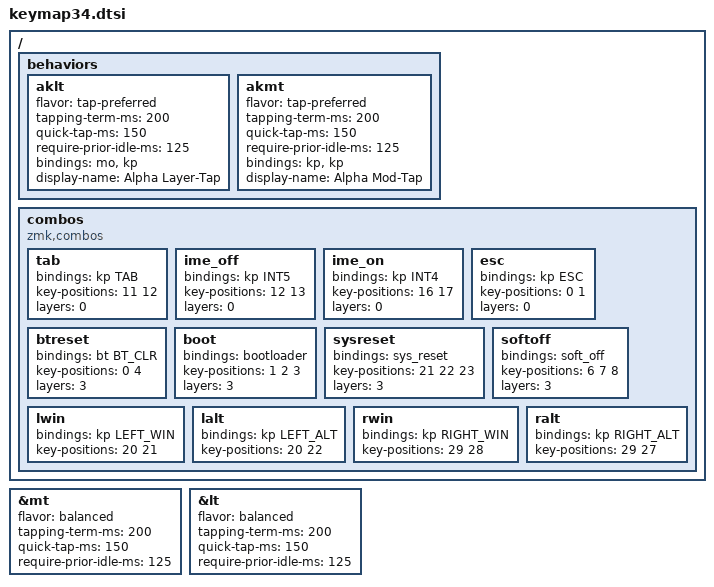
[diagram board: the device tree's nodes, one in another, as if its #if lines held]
/*
 * fue/keymap34.dtsi
 * jisaku_1(40キー) / aerogu34(34キー) 共通キーマップ定義
 *
 * ★キーマップを変えるときはこのファイルだけを編集する★
 * 変更をmainへpush後、各キーボードのリポジトリでGitHub Actionsを実行
 * (Run workflow)してビルドし直すと両機に反映される。
 *
 * 共通論理レイアウト(キー位置0〜33):
 *   0- 9: 上段10キー / 10-19: 中段10キー / 20-29: 下段10キー
 *  30-33: 親指4キー(SPACE / GRAVE / BACKSPACE / ENTER)
 * jisaku_1は最下段外側3キー×2を&noneで埋めて同一レイアウトにする。
 */

#ifndef FUE_KEYMAP34_DTSI
#define FUE_KEYMAP34_DTSI

#include <behaviors.dtsi>
#include <dt-bindings/zmk/keys.h>
#include <dt-bindings/zmk/bt.h>
#include <dt-bindings/zmk/pointing.h>

// ===== 実行時に変更できるホールドタップ(2026-11-27) =====
// zmk-feature-runtime-holdtap モジュールが west.yml にあれば、&lt / &mt と下の
// &aklt / &akmt を「zmk,behavior-runtime-hold-tap」ドライバに切り替える。
// flavor・tapping-term-ms などを DYA Studio の詳細設定(rt_holdtap)から
// ファーム書き換えなしで変更でき、下に書いた値はその既定値になる。
// モジュールが無いキーボードでは従来どおり標準ドライバのままビルドできる。
// (ホールドタップのドライバは全ホールドタップで揃える必要がある)
#if __has_include(<behaviors/runtime_hold_tap.dtsi>)
#include <behaviors/runtime_hold_tap.dtsi>
#define FUE_HOLD_TAP_COMPATIBLE ZMK_RUNTIME_HOLD_TAP_COMPATIBLE
#else
#define FUE_HOLD_TAP_COMPATIBLE "zmk,behavior-hold-tap"
#endif

// ===== JIS配列用キーコード定義(OS側が日本語配列設定の場合に正しい記号を出す) =====
#define JP_DQUOTE     AT                // "
#define JP_AMPERSAND  CARET             // &
#define JP_QUOTE      AMPERSAND         // '
#define JP_EQUAL      UNDER             // =
#define JP_CARET      EQUAL             // ^
#define JP_YEN        INT3              // ¥
#define JP_PLUS       COLON             // +
#define JP_TILDE      PLUS              // ~
#define JP_PIPE       LS(INT3)          // |
#define JP_AT         LEFT_BRACKET      // @
#define JP_COLON      SINGLE_QUOTE      // :
#define JP_ASTERISK   DOUBLE_QUOTES     // *
#define JP_BACKQUOTE  LEFT_BRACE        // `
#define JP_UNDERSCORE LS(INT1)          // _
#define JP_LBRACKET   RIGHT_BRACKET     // [
#define JP_RBRACKET   BACKSLASH         // ]
#define JP_LPAREN     ASTERISK          // (
#define JP_RPAREN     LEFT_PARENTHESIS  // )
#define JP_LBRACE     RIGHT_BRACE       // {
#define JP_RBRACE     PIPE              // }
#define JP_KANA       LANGUAGE_1        // かな
#define JP_EISU       LANGUAGE_2        // 英数
#define JP_HANZEN     GRAVE             // 半角/全角

// ===== ホールドタップ誤爆対策 =====
// balanced: 別キーが押して離されるまで完了したら長押し判定
// require-prior-idle-ms: 直前の打鍵から125ms以内は問答無用で単押し判定(ローリング誤爆根絶)
// quick-tap-ms: タップ直後150ms以内の再押下は単押し(キーリピート有効化)
&mt {
    flavor = "balanced";
    tapping-term-ms = <200>;
    quick-tap-ms = <150>;
    require-prior-idle-ms = <125>;
};

&lt {
    flavor = "balanced";
    tapping-term-ms = <200>;
    quick-tap-ms = <150>;
    require-prior-idle-ms = <125>;
};
// ↑ &mt / &lt は親指キー用(素早いレイヤー切替のため balanced のまま)。

// ===== 文字キー用ホールドタップ(2026-11-27) =====
// 文字キー(D/K/A/Z…)に balanced を使うと、「K押下→U押して離す→K離す」の
// ローリング(ローマ字の "ku" 等)が長押し判定になり、Win+Tab や BT切替が誤爆していた。
// 文字キーは tap-preferred にして「単独で tapping-term 以上押し続けた時だけ」長押しにする。
//   - 他キーを挟んでも長押しにならない → KU / DE / AT などのローリングで誤爆しない
//   - Kを押したままトラックボールを回す → 200ms後にScrollレイヤー(従来どおり)
//   - Ctrl+C 等は A を押したまま C → A を200ms以上保持すればCtrl+Cとして送出される
// DYA Studio上では「Alpha Layer-Tap」「Alpha Mod-Tap」として選択できる。
/ {
    behaviors {
        aklt: aklt {
            compatible = FUE_HOLD_TAP_COMPATIBLE;
            #binding-cells = <2>;
            flavor = "tap-preferred";
            tapping-term-ms = <200>;
            quick-tap-ms = <150>;
            require-prior-idle-ms = <125>;
            bindings = <&mo>, <&kp>;
            display-name = "Alpha Layer-Tap";
        };

        akmt: akmt {
            compatible = FUE_HOLD_TAP_COMPATIBLE;
            #binding-cells = <2>;
            flavor = "tap-preferred";
            tapping-term-ms = <200>;
            quick-tap-ms = <150>;
            require-prior-idle-ms = <125>;
            bindings = <&kp>, <&kp>;
            display-name = "Alpha Mod-Tap";
        };
    };
};

// ===== コンボ定義(両機共通: キー位置0〜29は同一) =====
/ {
    combos {
        compatible = "zmk,combos";

        tab {
            bindings = <&kp TAB>;
            key-positions = <11 12>;
            layers = <0>;
        };

        // ----- 日本語入力の切替 (2026-11-27) -----
        // D+F = IMEオフ(無変換) / J+K = IMEオン(変換)。今の状態に関係なく確実に切り替わる。
        // ※ Windows の MS-IME 設定で「無変換キー: IME-オフ」「変換キー: IME-オン」にしておくこと。
        // (旧 D+F=Shift+Tab は NumNavレイヤーの N に移動)
        ime_off {
            bindings = <&kp INT5>;
            key-positions = <12 13>;
            layers = <0>;
        };

        ime_on {
            bindings = <&kp INT4>;
            key-positions = <16 17>;
            layers = <0>;
        };

        // Q+W = Esc (Excelの入力取消・ダイアログを閉じる等)
        esc {
            bindings = <&kp ESC>;
            key-positions = <0 1>;
            layers = <0>;
        };

        // ----- Functionレイヤー(3)限定のシステム操作(誤爆防止) -----
        // BT_CLR: Q+T / Bootloader: W+E+R / sys_reset: X+C+V / soft_off: U+I+O
        btreset {
            bindings = <&bt BT_CLR>;
            key-positions = <0 4>;
            layers = <3>;
        };

        boot {
            bindings = <&bootloader>;
            key-positions = <1 2 3>;
            layers = <3>;
        };

        sysreset {
            bindings = <&sys_reset>;
            key-positions = <21 22 23>;
            layers = <3>;
        };

        softoff {
            bindings = <&soft_off>;
            key-positions = <6 7 8>;
            layers = <3>;
        };

        lwin {
            bindings = <&kp LEFT_WIN>;
            key-positions = <20 21>;
        };

        lalt {
            bindings = <&kp LEFT_ALT>;
            key-positions = <20 22>;
        };

        rwin {
            bindings = <&kp RIGHT_WIN>;
            key-positions = <29 28>;
        };

        ralt {
            bindings = <&kp RIGHT_ALT>;
            key-positions = <29 27>;
        };
    };
};

// ===== レイヤー定義マクロ =====
// 各行10キー(左5+右5)、THUMBSは親指4キー(左2+右2)
// 2026-11-27 全面見直し: Excel / スプレッドシート / Chrome / チャット中心の使い方に合わせた。
//   1: Symbol   … 記号をすべて集約 (上段 = Shift+数字と同じ並び)
//   2: NumNav   … 左手テンキー + 右手カーソル/ページ移動/タブ切替
//   3: Function … F1〜F12・音量・BT切替・更新モード (ボールはスクロール)
//   4: Mouse    … ボールを動かすと自動で入る。クリック・スクロール・精密モード

// 精密モード(押している間ポインター速度0.5倍): runtime-input-processor がある機種のみ
#if __has_include(<behaviors/runtime-input-processor.dtsi>)
#include <behaviors/runtime-input-processor.dtsi>
#define FUE_PRECISION_KEY &rip_ldpi
#else
#define FUE_PRECISION_KEY &trans
#endif

// 更新モードキー: Functionレイヤーの B(左) / N(右) で、押した側のハーフを
// USBシリアル更新モード(&ser_dfu)で再起動する。zmk-feature-ota-dfu が無い構成では &trans。
#if __has_include(<behaviors/ota_dfu.dtsi>)
#define FUE_DFU_KEY &ser_dfu
#else
#define FUE_DFU_KEY &trans
#endif

// --- Layer 0: Default ---
#define FUE_L0_ROW1 &kp Q &kp W &kp E &kp R &kp T    &kp Y &kp U &kp I &kp O &kp P
#define FUE_L0_ROW2 &akmt LCTRL A &kp S &aklt 3 D &kp F &kp G    &kp H &kp J &aklt 3 K &kp L &akmt RCTRL MINUS
#define FUE_L0_ROW3 &akmt LSHIFT Z &akmt LGUI X &akmt LALT C &kp V &kp B    &kp N &kp M &akmt RALT COMMA &akmt RGUI DOT &akmt RSHIFT SLASH
#define FUE_L0_THUMBS &lt 1 SPACE &lt 3 GRAVE    &kp BACKSPACE &lt 2 ENTER

// --- Layer 1: Symbol ---
//  !  "  #  $  %    &  '  (  )  ~
//  =  +  -  *  /    ^  @  :  ;  ¥
//  <  >  _  |  `    ?  [  ]  {  }
#define FUE_L1_ROW1 &kp EXCLAMATION &kp JP_DQUOTE &kp HASH &kp DOLLAR &kp PERCENT    &kp JP_AMPERSAND &kp JP_QUOTE &kp JP_LPAREN &kp JP_RPAREN &kp JP_TILDE
#define FUE_L1_ROW2 &kp JP_EQUAL &kp JP_PLUS &kp MINUS &kp JP_ASTERISK &kp SLASH    &kp JP_CARET &kp JP_AT &kp JP_COLON &kp SEMICOLON &kp JP_YEN
#define FUE_L1_ROW3 &kp LS(COMMA) &kp LS(DOT) &kp JP_UNDERSCORE &kp JP_PIPE &kp JP_BACKQUOTE    &kp QUESTION &kp JP_LBRACKET &kp JP_RBRACKET &kp JP_LBRACE &kp JP_RBRACE
#define FUE_L1_THUMBS &trans &trans    &trans &trans

// --- Layer 2: NumNav ---
//  Tab 7 8 9 =     PgUp Home ↑    End  Del
//  *   4 5 6 +     PgDn ←    ↓    →    F2
//  /   1 2 3 -     S-Tab C-PgUp C-PgDn A-Enter S-Enter
//  (親指) . 0
// C-PgUp/C-PgDn = Excelのシート切替・Chromeのタブ切替
// A-Enter = Excelのセル内改行 / S-Enter = チャットで送信せずに改行
#define FUE_L2_ROW1 &kp TAB &kp N7 &kp N8 &kp N9 &kp JP_EQUAL    &kp PG_UP &kp HOME &kp UP &kp END &kp DEL
#define FUE_L2_ROW2 &kp JP_ASTERISK &kp N4 &kp N5 &kp N6 &kp JP_PLUS    &kp PG_DN &kp LEFT &kp DOWN &kp RIGHT &kp F2
#define FUE_L2_ROW3 &kp SLASH &kp N1 &kp N2 &kp N3 &kp MINUS    &kp LS(TAB) &kp LC(PG_UP) &kp LC(PG_DN) &kp LA(ENTER) &kp LS(ENTER)
#define FUE_L2_THUMBS &kp DOT &kp N0    &trans &trans

// --- Layer 3: Function (ボール = スクロール) ---
//  F1  F2  F3   F4   F5       F6   F7  F8  F9  F10
//  F11 F12 Vol- Vol+ 切取り   戻る 左  中  右  進む   (マウスボタン)
//  BT0 BT1 BT2  BT3  更新     更新 ←デスクトップ タスクビュー デスクトップ→ Studio解除
#define FUE_L3_ROW1 &kp F1 &kp F2 &kp F3 &kp F4 &kp F5    &kp F6 &kp F7 &kp F8 &kp F9 &kp F10
#define FUE_L3_ROW2 &kp F11 &kp F12 &kp C_VOL_DN &kp C_VOL_UP &kp LG(LS(S))    &mkp MB4 &mkp MB1 &mkp MB3 &mkp MB2 &mkp MB5
#define FUE_L3_ROW3 &bt BT_SEL 0 &bt BT_SEL 1 &bt BT_SEL 2 &bt BT_SEL 3 FUE_DFU_KEY    FUE_DFU_KEY &kp LC(LG(LEFT)) &kp LG(TAB) &kp LC(LG(RIGHT)) &studio_unlock
#define FUE_L3_THUMBS &trans &trans    &trans &trans

// --- Layer 4: Mouse (ボールを動かすと自動で有効) ---
// J=左クリック K=押している間スクロール L=右クリック -=押している間 精密(0.5倍)
// Z=Shift X=Ctrl (Shift+クリックで範囲選択、Ctrl+クリックで複数選択、Ctrl+スクロールでズーム)
// それ以外のキーは押した瞬間に通常入力へ戻る。
#define FUE_L4_ROW1 &trans &trans &trans &trans &trans    &trans &trans &trans &trans &trans
#define FUE_L4_ROW2 &trans &trans &trans &trans &trans    &trans &mkp MB1 &mo 3 &mkp MB2 FUE_PRECISION_KEY
#define FUE_L4_ROW3 &kp LSHIFT &kp LCTRL &trans &trans &trans    &trans &trans &trans &trans &trans
#define FUE_L4_THUMBS &trans &trans    &trans &trans

#endif /* FUE_KEYMAP34_DTSI */
